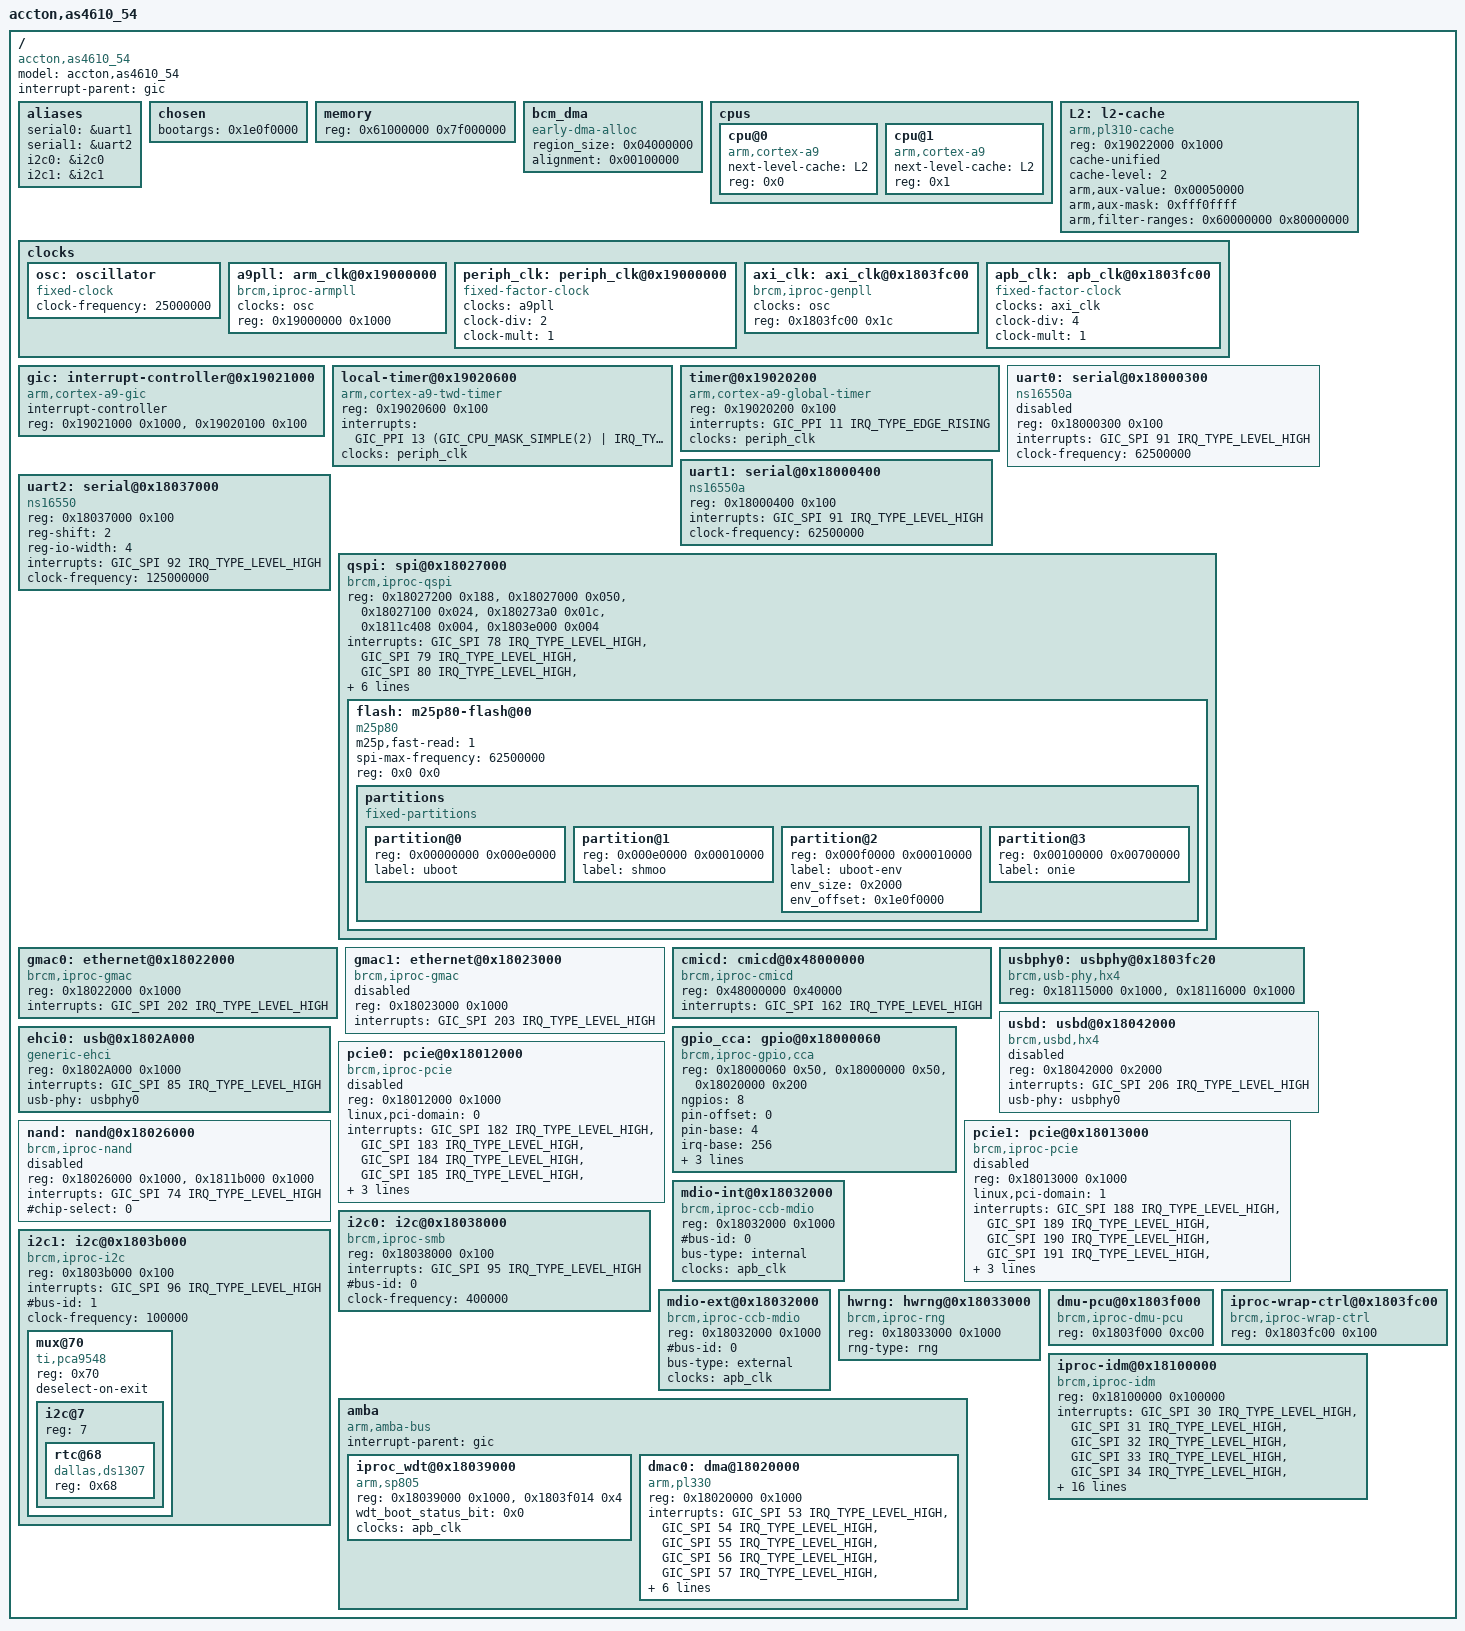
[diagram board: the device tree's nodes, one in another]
/*
 * Accton AS4610 54 Device Tree Source
 *
 * Copyright 2015, Cumulus Networks, Inc.
 *
 * This program is free software; you can redistribute  it and/or modify it
 * under  the terms of  the GNU General  Public License as published by the
 * Free Software Foundation;  either version 2 of the  License, or (at your
 * option) any later version.
 *
 */

/dts-v1/;

#include <dt-bindings/interrupt-controller/arm-gic.h>
#include <dt-bindings/gpio/gpio.h>
#include "skeleton.dtsi"


/ {
	model = "accton,as4610_54";
	compatible = "accton,as4610_54";
	interrupt-parent = <&gic>;

	aliases {
		serial0 = &uart1;
		serial1 = &uart2;
		i2c0 = &i2c0;
		i2c1 = &i2c1;
	};

        chosen {
                bootargs = "console=ttyS0,115200n8 maxcpus=2, envaddr = <0x1e0f0000>";
        };

	memory {
		reg = <0x61000000 0x7f000000>;
	};

	bcm_dma {
		compatible = "early-dma-alloc";
		// 64MB DMA region, aligned to 1MB
		region_size = <0x04000000>;
		alignment = <0x00100000>;
	};

	cpus {
		#address-cells = <1>;
		#size-cells = <0>;

		cpu@0 {
			device_type = "cpu";
			compatible = "arm,cortex-a9";
			next-level-cache = <&L2>;
			reg = <0x0>;
		};

		cpu@1 {
			device_type = "cpu";
			compatible = "arm,cortex-a9";
			next-level-cache = <&L2>;
			reg = <0x1>;
		};
	};

	L2: l2-cache {
		compatible = "arm,pl310-cache";
		reg = <0x19022000 0x1000>;
		cache-unified;
		cache-level = <2>;
		/* aux register value */
		arm,aux-value = <0x00050000>;
		arm,aux-mask = <0xfff0ffff>;
		arm,filter-ranges = <0x60000000 0x80000000>;
		/*arm,data-latency = <2 2 2>;*/
		/*arm,tag-latency = <1 1 1>;*/
	};

	clocks {
		#address-cells = <1>;
		#size-cells = <1>;
		ranges;

		osc: oscillator {
			#clock-cells = <0>;
			compatible = "fixed-clock";
			clock-frequency = <25000000>;
		};

		a9pll: arm_clk@0x19000000 {
			#clock-cells = <0>;
			compatible = "brcm,iproc-armpll";
			clocks = <&osc>;
			reg = <0x19000000 0x1000>;
		};

		periph_clk: periph_clk@0x19000000 {
			#clock-cells = <0>;
			compatible = "fixed-factor-clock";
			clocks = <&a9pll>;
			clock-div = <2>;
			clock-mult = <1>;
		};

		axi_clk: axi_clk@0x1803fc00 {
			#clock-cells = <0>;
			compatible = "brcm,iproc-genpll";
			clocks = <&osc>;
			reg = <0x1803fc00 0x1c>;
		};

		apb_clk: apb_clk@0x1803fc00 {
			#clock-cells = <0>;
			compatible = "fixed-factor-clock";
			clocks = <&axi_clk>;
			clock-div = <4>;
			clock-mult = <1>;
		};
	};

	gic: interrupt-controller@0x19021000 {
		compatible = "arm,cortex-a9-gic";
		#interrupt-cells = <3>;
		interrupt-controller;
		reg = <0x19021000 0x1000>, <0x19020100 0x100>;
	};

	local-timer@0x19020600 {
		compatible = "arm,cortex-a9-twd-timer";
		reg = <0x19020600 0x100>;
		/*
		 * bits[15:8] PPI interrupt cpu mask. Each bit
		 * corresponds to each of the 8 possible cpus
		 * attached to the GIC
		 */
		interrupts = <GIC_PPI 13  (GIC_CPU_MASK_SIMPLE(2) | IRQ_TYPE_EDGE_RISING)>;
		clocks = <&periph_clk>;
	};

	timer@0x19020200 {
		compatible = "arm,cortex-a9-global-timer";
		reg = <0x19020200 0x100>;
		interrupts = <GIC_PPI 11 IRQ_TYPE_EDGE_RISING>;
		clocks = <&periph_clk>;
	};

	uart0: serial@0x18000300 {
		compatible = "ns16550a";
		reg = <0x18000300 0x100>;
		interrupts = <GIC_SPI 91 IRQ_TYPE_LEVEL_HIGH>;
		clock-frequency = <62500000>;
		status = "disabled";
	};

	uart1: serial@0x18000400 {
		compatible = "ns16550a";
		reg = <0x18000400 0x100>;
		interrupts = <GIC_SPI 91 IRQ_TYPE_LEVEL_HIGH>;
		clock-frequency = <62500000>;
		/*status = "disabled";*/
	};

	uart2: serial@0x18037000 {
		compatible = "ns16550";
		reg = <0x18037000 0x100>;
		reg-shift = <2>;
		reg-io-width = <4>;
		interrupts = <GIC_SPI 92 IRQ_TYPE_LEVEL_HIGH>;
		clock-frequency = <125000000>;
	};

	qspi: spi@0x18027000 {
		#address-cells = <1>;
		#size-cells = <0>;
		compatible = "brcm,iproc-qspi";
		reg = mspi_hw:<0x18027200 0x188>,
		      bspi_hw:<0x18027000 0x050>,
		  bspi_hw_raf:<0x18027100 0x024>,
		    qspi_intr:<0x180273a0 0x01c>,
		     idm_qspi:<0x1811c408 0x004>,
		       cru_hw:<0x1803e000 0x004>;
		interrupts = <GIC_SPI 78 IRQ_TYPE_LEVEL_HIGH>,
					<GIC_SPI 79 IRQ_TYPE_LEVEL_HIGH>,
					<GIC_SPI 80 IRQ_TYPE_LEVEL_HIGH>,
					<GIC_SPI 81 IRQ_TYPE_LEVEL_HIGH>,
					<GIC_SPI 82 IRQ_TYPE_LEVEL_HIGH>,
					<GIC_SPI 83 IRQ_TYPE_LEVEL_HIGH>,
					<GIC_SPI 84 IRQ_TYPE_LEVEL_HIGH>;
		#chip-select = <0>;
		clocks = <&apb_clk>;
		clock-names = "apb_clk";
		flash: m25p80-flash@00 {
			compatible = "m25p80";
			m25p,fast-read = <1>;
			spi-max-frequency = <62500000>;
			reg = <0x0 0x0>;

			partitions {
				compatible = "fixed-partitions";
				#address-cells = <1>;
				#size-cells = <1>;
				partition@0 {
					/* uboot */
					reg = <0x00000000 0x000e0000>;
					label = "uboot";
				};
				partition@1 {
					/* shmoo */
					reg = <0x000e0000 0x00010000>;
					label = "shmoo";
				};
				partition@2 {
					/* uboot-env */
					reg = <0x000f0000 0x00010000>;
					label = "uboot-env";
					env_size = <0x2000>;
					env_offset = <0x1e0f0000>;
				};
				partition@3 {
					/* onie */
					reg = <0x00100000 0x00700000>;
					label = "onie";
				};
			};
		};
	};

	gmac0: ethernet@0x18022000 {
		compatible = "brcm,iproc-gmac";
		reg = <0x18022000 0x1000>;
		interrupts = <GIC_SPI 202 IRQ_TYPE_LEVEL_HIGH>;
	};

	gmac1: ethernet@0x18023000 {
		compatible = "brcm,iproc-gmac";
		reg = <0x18023000 0x1000>;
		interrupts = <GIC_SPI 203 IRQ_TYPE_LEVEL_HIGH>;
		status = "disabled";
	};

	cmicd: cmicd@0x48000000 {
		compatible = "brcm,iproc-cmicd";
		reg = <0x48000000 0x40000>;
		interrupts = <GIC_SPI 162 IRQ_TYPE_LEVEL_HIGH>;

	};

	usbphy0: usbphy@0x1803fc20 {
		#phy-cells = <0>;
		compatible = "brcm,usb-phy,hx4";
		reg = idm_usb2h: <0x18115000 0x1000>,
		      idm_usb2d: <0x18116000 0x1000>;
	};

	usbd: usbd@0x18042000 {
		compatible = "brcm,usbd,hx4";
		reg = <0x18042000 0x2000>;
		interrupts = <GIC_SPI 206 IRQ_TYPE_LEVEL_HIGH>;
		usb-phy = <&usbphy0>;
		status = "disabled";
	};

	ehci0: usb@0x1802A000 {
		compatible = "generic-ehci";
		reg = <0x1802A000 0x1000>;
		interrupts = <GIC_SPI 85 IRQ_TYPE_LEVEL_HIGH>;
		usb-phy = <&usbphy0>;
	};

	gpio_cca: gpio@0x18000060 {
		compatible = "brcm,iproc-gpio,cca";
		#address-cells = <1>;
		#size-cells = <1>;
		#gpio-cells = <2>;
		reg = gpio: <0x18000060 0x50>,
		      intr: <0x18000000 0x50>,
		       dmu: <0x18020000 0x200>;
		ngpios = <8>;
		pin-offset = <0>;
		pin-base = <4>;
		irq-base = <256>; /* sw irq base for irq handlers */
		gpio-controller;
		interrupt-controller;
		interrupts = <GIC_SPI 91 IRQ_TYPE_LEVEL_HIGH>;
	};

	pcie0: pcie@0x18012000 {
		compatible = "brcm,iproc-pcie", "iproc-p2";
		reg = <0x18012000 0x1000>;
		linux,pci-domain = <0>;
		interrupts = <GIC_SPI 182 IRQ_TYPE_LEVEL_HIGH>,
			     <GIC_SPI 183 IRQ_TYPE_LEVEL_HIGH>,
			     <GIC_SPI 184 IRQ_TYPE_LEVEL_HIGH>,
			     <GIC_SPI 185 IRQ_TYPE_LEVEL_HIGH>,
			     <GIC_SPI 186 IRQ_TYPE_LEVEL_HIGH>,
			     <GIC_SPI 187 IRQ_TYPE_LEVEL_HIGH>;
		status = "disabled";
		#address-cells = <3>;
		#size-cells = <2>;
		device_type = "pci";
		/*
		 * non-prefetchable mem space, pcie addr 0x0 0x08000000,
		 * cpu addr 0x08000000, size 0x0 0x08000000
		 */
		ranges = <0x82000000 0 0x08000000 0x08000000 0 0x08000000>;
		phy-addr = <0>;
	};

	pcie1: pcie@0x18013000 {
		compatible = "brcm,iproc-pcie", "iproc-p2";
		reg = <0x18013000 0x1000>;
		linux,pci-domain = <1>;
		interrupts = <GIC_SPI 188 IRQ_TYPE_LEVEL_HIGH>,
			     <GIC_SPI 189 IRQ_TYPE_LEVEL_HIGH>,
			     <GIC_SPI 190 IRQ_TYPE_LEVEL_HIGH>,
			     <GIC_SPI 191 IRQ_TYPE_LEVEL_HIGH>,
			     <GIC_SPI 192 IRQ_TYPE_LEVEL_HIGH>,
			     <GIC_SPI 193 IRQ_TYPE_LEVEL_HIGH>;
		status = "disabled";
		#address-cells = <3>;
		#size-cells = <2>;
		device_type = "pci";
		/*
		 * non-prefetchable mem space, pcie addr 0x0 0x40000000,
		 * cpu addr 0x40000000, size 0x0 0x08000000
		 */
		ranges = <0x82000000 0 0x40000000 0x40000000 0 0x08000000>;
		phy-addr = <1>;
	};

	nand: nand@0x18026000 {
		compatible = "brcm,iproc-nand";
		reg =	nand_regs: <0x18026000 0x1000>,
			nand_idm_regs: <0x1811b000 0x1000>;
		interrupts = <GIC_SPI 74 IRQ_TYPE_LEVEL_HIGH>;
		#chip-select = <0>;
		#address-cells = <1>;
		#size-cells = <1>;
		status = "disabled";
	};

	i2c0: i2c@0x18038000 {
		compatible = "brcm,iproc-smb";
		reg = <0x18038000 0x100>;
		interrupts = <GIC_SPI 95 IRQ_TYPE_LEVEL_HIGH>;
		#bus-id = <0>;
		clock-frequency = <400000>;
		#address-cells = <1>;
		#size-cells = <0>;
	};

	i2c1: i2c@0x1803b000 {
		compatible = "brcm,iproc-i2c";
		reg = <0x1803b000 0x100>;
		interrupts = <GIC_SPI 96 IRQ_TYPE_LEVEL_HIGH>;
		#bus-id = <1>;
		clock-frequency = <100000>;
		#address-cells = <1>;
		#size-cells = <0>;
		mux@70 {
			#address-cells = <1>;
			#size-cells = <0>;
			compatible = "ti,pca9548";
			reg = <0x70>;
			deselect-on-exit;

			i2c@7 {
				#address-cells = <1>;
				#size-cells = <0>;
				reg = <7>;

				rtc@68 {
					/* Actually M41T11 */
					compatible = "dallas,ds1307";
					reg = <0x68>;
				};
			};
		};
	};

	mdio-int@0x18032000 {
		compatible = "brcm,iproc-ccb-mdio";
		#address-cells = <1>;
		#size-cells = <1>;
		reg = <0x18032000 0x1000>;
		#bus-id = <0>;
		bus-type = "internal";
		clocks = <&apb_clk>;
		clock-names = "apb_clk";
	};

	mdio-ext@0x18032000 {
		compatible = "brcm,iproc-ccb-mdio";
		#address-cells = <1>;
		#size-cells = <1>;
		reg = <0x18032000 0x1000>;
		/*
		 * cmicd mdio needs #logical-bus-id in
		 * addition to #bus-id (physical)
		 */
		#bus-id = <0>;
		bus-type = "external";
		clocks = <&apb_clk>;
		clock-names = "apb_clk";
	};

	hwrng: hwrng@0x18033000 {
		compatible = "brcm,iproc-rng";
		#address-cells = <1>;
		#size-cells = <1>;
		reg = <0x18033000 0x1000>;
		rng-type = "rng";
	};

	amba {
		#address-cells = <1>;
		#size-cells = <1>;
		compatible = "arm,amba-bus", "simple-bus";
		interrupt-parent = <&gic>;
		ranges;

		iproc_wdt@0x18039000 {
			compatible = "arm,sp805", "arm,primecell";
			reg = iproc_wdt_base: <0x18039000 0x1000>,
			iproc_reset_reg: <0x1803f014 0x4>;
			wdt_boot_status_bit = <0x0>;
			clocks = <&apb_clk>;
			/* should be "apb_pclk" according to
			 *Documentation/devicetree/bindings/arm/primecell.txt
			 */
			clock-names = "apb_pclk";
		};

		dmac0: dma@18020000 {
			compatible = "arm,pl330", "arm,primecell";
			reg = pl330_base: <0x18020000 0x1000>; /* SB2: 0x18018000 */
			/* HR3:72, GH/SB2/GH2:84, HX4/KT2/HR2:85 */
			interrupts = <GIC_SPI 53 IRQ_TYPE_LEVEL_HIGH>,
			             <GIC_SPI 54 IRQ_TYPE_LEVEL_HIGH>,
			             <GIC_SPI 55 IRQ_TYPE_LEVEL_HIGH>,
			             <GIC_SPI 56 IRQ_TYPE_LEVEL_HIGH>,
			             <GIC_SPI 57 IRQ_TYPE_LEVEL_HIGH>,
			             <GIC_SPI 58 IRQ_TYPE_LEVEL_HIGH>,
			             <GIC_SPI 59 IRQ_TYPE_LEVEL_HIGH>,
			             <GIC_SPI 60 IRQ_TYPE_LEVEL_HIGH>;
			/*arm,primecell-periphid = <0x00041330>;*/
			clocks = <&apb_clk>;
			clock-names = "apb_pclk";
			#dma-cells = <1>;
			#dma-channels = <8>;
			#dma-requests = <16>;
		};
	};

	dmu-pcu@0x1803f000 {
		compatible = "brcm,iproc-dmu-pcu";
		#address-cells = <1>;
		#size-cells = <1>;
		reg = dmu_pcu: <0x1803f000 0xc00>;
	};

	iproc-wrap-ctrl@0x1803fc00 {
		compatible = "brcm,iproc-wrap-ctrl";
		#address-cells = <1>;
		#size-cells = <1>;
		reg = <0x1803fc00 0x100>;
	};

	iproc-idm@0x18100000 {
		compatible = "brcm,iproc-idm";
		#address-cells = <1>;
		#size-cells = <1>;
		reg = <0x18100000 0x100000>;
		interrupts = <GIC_SPI 30 IRQ_TYPE_LEVEL_HIGH>,
		             <GIC_SPI 31 IRQ_TYPE_LEVEL_HIGH>,
		             <GIC_SPI 32 IRQ_TYPE_LEVEL_HIGH>,
		             <GIC_SPI 33 IRQ_TYPE_LEVEL_HIGH>,
		             <GIC_SPI 34 IRQ_TYPE_LEVEL_HIGH>,
		             <GIC_SPI 35 IRQ_TYPE_LEVEL_HIGH>,
		             <GIC_SPI 36 IRQ_TYPE_LEVEL_HIGH>,
		             <GIC_SPI 37 IRQ_TYPE_LEVEL_HIGH>,
		             <GIC_SPI 38 IRQ_TYPE_LEVEL_HIGH>,
		             <GIC_SPI 39 IRQ_TYPE_LEVEL_HIGH>,
		             <GIC_SPI 41 IRQ_TYPE_LEVEL_HIGH>,
		             <GIC_SPI 42 IRQ_TYPE_LEVEL_HIGH>,
		             <GIC_SPI 43 IRQ_TYPE_LEVEL_HIGH>,
		             <GIC_SPI 44 IRQ_TYPE_LEVEL_HIGH>,
		             <GIC_SPI 45 IRQ_TYPE_LEVEL_HIGH>,
		             <GIC_SPI 46 IRQ_TYPE_LEVEL_HIGH>,
		             <GIC_SPI 47 IRQ_TYPE_LEVEL_HIGH>,
		             <GIC_SPI 48 IRQ_TYPE_LEVEL_HIGH>,
		             <GIC_SPI 49 IRQ_TYPE_LEVEL_HIGH>,
		             <GIC_SPI 50 IRQ_TYPE_LEVEL_HIGH>,
		             <GIC_SPI 51 IRQ_TYPE_LEVEL_HIGH>;
	};
};
